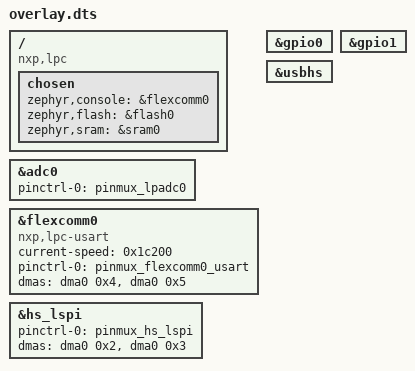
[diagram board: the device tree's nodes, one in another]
/ {
	compatible = "nxp,lpc", "nxp,lpc55xxx";
	chosen {
		zephyr,console = &flexcomm0;
		zephyr,flash = &flash0;
		zephyr,sram = &sram0;
	};
};
&adc0{
	status = "okay";
	pinctrl-0 = < &pinmux_lpadc0 >;
	pinctrl-names = "default";
};
&flexcomm0{
	compatible = "nxp,lpc-usart";
	status = "okay";
	current-speed = < 0x1c200 >;
	pinctrl-0 = < &pinmux_flexcomm0_usart >;
	pinctrl-names = "default";
	dmas = < &dma0 0x4 >, < &dma0 0x5 >;
	dma-names = "rx", "tx";
};
&gpio0{
	status = "okay";
};
&gpio1{
	status = "okay";
};
&hs_lspi{
	status = "okay";
	pinctrl-0 = < &pinmux_hs_lspi >;
	pinctrl-names = "default";
	dmas = < &dma0 0x2 >, < &dma0 0x3 >;
	dma-names = "rx", "tx";
};
&usbhs{
	status = "okay";
};
